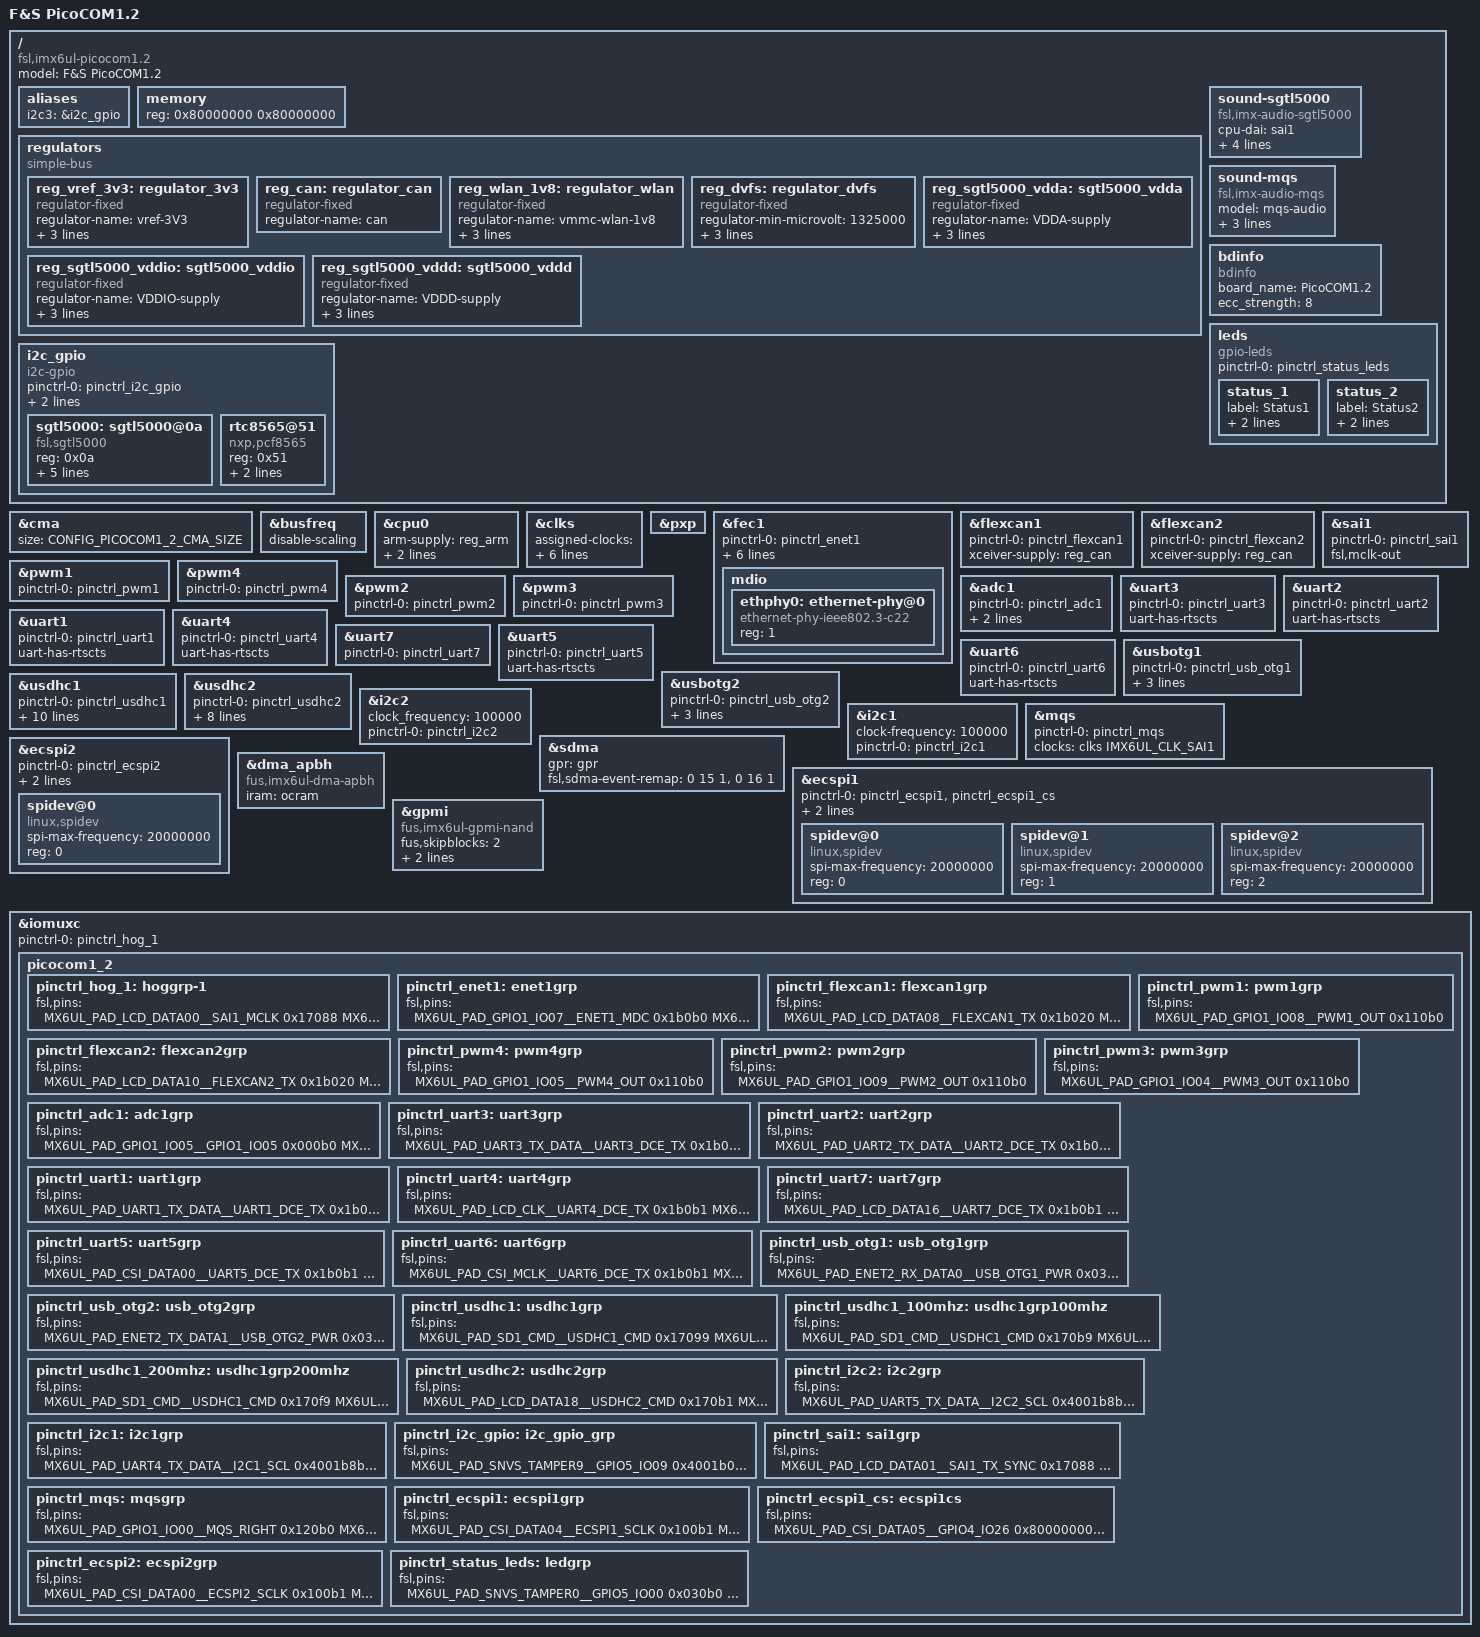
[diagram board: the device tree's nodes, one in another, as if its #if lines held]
/*
 * Copyright (C) 2016-2019 F&S Elektronik Systeme GmbH
 *
 * This program is free software; you can redistribute it and/or modify
 * it under the terms of the GNU General Public License version 2 as
 * published by the Free Software Foundation.
 */

/dts-v1/;

/* Set board revision as 3-digit number, e.g. 110 for board rev. 1.10 */
#define CONFIG_PICOCOM1_2_BOARD_REVISION	100

/* CMA: Set 64 MB for Continuous Memory Allocator */
#define CONFIG_PICOCOM1_2_CMA_SIZE 0x4000000

/* Ethernet, pins 1-4/71 */
#define CONFIG_PICOCOM1_2_ETH_A

/* WLAN/BLUETOOTH */
#define CONFIG_PICOCOM1_2_WLAN
//#define CONFIG_PICOCOM1_2_BLUETOOTH

/*
 * USB Device/OTG, pins 21/22/23. Set CONFIG_PICOCOM1_2_USB_OTG_HOST, if you
 * want to use OTG as a second host port, PWR is on pin 29 then.
 * ### TODO: Add support for role switch, ID is available on pin 17 as option.
 */
#define CONFIG_PICOCOM1_2_USB_OTG
//#define CONFIG_PICOCOM1_2_USB_OTG_HOST

/* USB Host, pins 19/20, PWR on pin 24 */
#define CONFIG_PICOCOM1_2_USB_HOST

/* CAN: CAN_A on pins 51/52, CAN_B on pins 53/54 */
#define CONFIG_PICOCOM1_2_CAN_A
#define CONFIG_PICOCOM1_2_CAN_B

/* I2C: I2C_A on pins 32/33, I2C_B on pins 12/11 */
#define CONFIG_PICOCOM1_2_I2C_A
#define CONFIG_PICOCOM1_2_I2C_B

/* PWM: PWM_A on pin 74, PWM_B on pin 75, PWM_C on pin 76, PWM_D on pin 70 */
#define CONFIG_PICOCOM1_2_PWM_A
#define CONFIG_PICOCOM1_2_PWM_B
#define CONFIG_PICOCOM1_2_PWM_C
#define CONFIG_PICOCOM1_2_PWM_D

/*
 * UART:
 * - UART_A with TXD/RXD/RTS/CTS on pins 17/18/49/50
 * - UART_B with TXD/RXD/RTS/CTS on pins 13-16
 * - UART_C with TXD/RXD/RTS/CTS on pins 43/44/41/40,
 * - UART_D with TXD/RXD/RTS/CTS on pins 45-48
 * - UART_E with TXD/RXD only on pins 67/68,
 * - UART_F with TXD/RXD/RTS/CTS on pins 63-66 (available if SPI_B is not used)
 * Comment the line with the RTSCTS macro if you just need TXD/RXD on a port
 */
#define CONFIG_PICOCOM1_2_UART_A
#define CONFIG_PICOCOM1_2_UART_A_RTSCTS
#define CONFIG_PICOCOM1_2_UART_B
#define CONFIG_PICOCOM1_2_UART_B_RTSCTS
#define CONFIG_PICOCOM1_2_UART_C
#define CONFIG_PICOCOM1_2_UART_C_RTSCTS
#define CONFIG_PICOCOM1_2_UART_D
#define CONFIG_PICOCOM1_2_UART_D_RTSCTS
#define CONFIG_PICOCOM1_2_UART_E
#define CONFIG_PICOCOM1_2_UART_F
#define CONFIG_PICOCOM1_2_UART_F_RTSCTS

/* SPI: SPI_A (3x CS) on pins 55-60, SPI_B (1x CS) on pins 63-66 */
#define CONFIG_PICOCOM1_2_SPI_A
#define CONFIG_PICOCOM1_2_SPI_B

/* Audio: Codec (SGTL5000) on pins 77-80 */
#define CONFIG_PICOCOM1_2_AUDIO

/*
 * MQS (Medium Quality Sound, playback only) on pins 77/78 is a hardware option
 * and only available if the SGTL5000 audio codec is not equipped.
 */
//#define CONFIG_PICOCOM1_2_MQS

/*
 * SD-Card, pins 34-39, CD on pin 40, WP on pin 41
 * The PicoCOM1 SKIT does not support CD and WP.
 */
#define CONFIG_PICOCOM1_2_SD_A
//#define CONFIG_PICOCOM1_2_SD_A_CD
//#define CONFIG_PICOCOM1_2_SD_A_WP

/*
 * ADC, pins 74-76. These pins are shared with PWM_A to PWM_C, so undefine the
 * PWM configs if you want to use them for analog input, otherwise you will
 * only measure the PWM level and the PWM output will work against the input.
 */
#define CONFIG_PICOCOM1_2_ADC


/* Check for invalid CONFIG combinations */

/* If SPI_B is active, UART_F can not be used */
#ifdef CONFIG_PICOCOM1_2_SPI_B
#undef CONFIG_PICOCOM1_2_UART_F
#undef CONFIG_PICOCOM1_2_UART_F_RTSCTS
#endif

/* If UART_C uses RTS/CTS, CD and WP for SD_A can not be used */
#ifdef CONFIG_PICOCOM1_2_UART_C_RTSCTS
#undef CONFIG_PICOCOM1_2_SD_A_CD
#undef CONFIG_PICOCOM1_2_SD_A_WP
#endif

/* If SGTL5000 audio is available, MQS audio can not be used */
#ifdef CONFIG_PICOCOM1_2_AUDIO
#undef CONFIG_PICOCOM1_2_MQS
#endif

/* If ADC is available, PWM_A - PWM_C can not be used */
#ifdef CONFIG_PICOCOM1_2_ADC
#undef CONFIG_PICOCOM1_2_PWM_A
#undef CONFIG_PICOCOM1_2_PWM_B
#undef CONFIG_PICOCOM1_2_PWM_C
#endif

#include <dt-bindings/input/input.h>
#include "imx6ul.dtsi"

/ {
	model = "F&S PicoCOM1.2";
	compatible = "fsl,imx6ul-picocom1.2", "fsl,imx6ul";

	aliases {
		i2c3 = &i2c_gpio;
	};

#if 0
chosen {
		stdout-path = &uart1;
	};
#endif
	memory {
		reg = <0x80000000 0x80000000>;
	};

	regulators {
		compatible = "simple-bus";
		#address-cells = <1>;
		#size-cells = <0>;

		reg_vref_3v3: regulator_3v3 {
			compatible = "regulator-fixed";
			regulator-name = "vref-3V3";
			regulator-min-microvolt = <3300000>;
			regulator-max-microvolt = <3300000>;
			regulator-always-on;
		};

		reg_can: regulator_can {
			compatible = "regulator-fixed";
			regulator-name = "can";
		};

#ifdef CONFIG_PICOCOM1_2_WLAN
		reg_wlan_1v8: regulator_wlan {
			compatible = "regulator-fixed";
			regulator-name = "vmmc-wlan-1v8";
			regulator-min-microvolt = <1800000>;
			regulator-max-microvolt = <1800000>;
			regulator-always-on;
		};
#endif

		reg_dvfs: regulator_dvfs {
			compatible = "regulator-fixed";
			regulator-min-microvolt = <1325000>;
			regulator-max-microvolt = <1325000>;
			regulator-name = "dvfs";
			regulator-always-on;
		};

		/* USB_OTG1_PWR done by USB controller, no regulator needed */
#if 0 //###
		reg_usb_otg1_vbus: usb_otg1_vbus {
			compatible = "regulator-fixed";
			regulator-name = "usb_otg1_vbus";
			regulator-min-microvolt = <5000000>;
			regulator-max-microvolt = <5000000>;
			gpio = <&gpio2 8 0>;
			enable-active-high;
		};
#endif //###

		/* USB_OTG2_PWR done by USB controller, no regulator needed */
#if 0 //###
		reg_usb_otg2_vbus: usb_otg2_vbus {
			compatible = "regulator-fixed";
			regulator-name = "usb_otg2_vbus";
			regulator-min-microvolt = <5000000>;
			regulator-max-microvolt = <5000000>;
			gpio = <&gpio2 12 0>;
			enable-active-high;
		};
#endif //###

#ifdef CONFIG_PICOCOM1_2_AUDIO
		/* SGTL5000 analog voltage */
		reg_sgtl5000_vdda: sgtl5000_vdda {
			compatible = "regulator-fixed";
			regulator-name = "VDDA-supply";
			regulator-min-microvolt = <3000000>;
			regulator-max-microvolt = <3000000>;
			regulator-always-on;
		};

		/* SGTL5000 I/O voltage */
		reg_sgtl5000_vddio: sgtl5000_vddio {
			compatible = "regulator-fixed";
			regulator-name = "VDDIO-supply";
			regulator-min-microvolt = <3300000>;
			regulator-max-microvolt = <3300000>;
			regulator-always-on;
		};

		/* SGTL5000 internal digital voltage */
		reg_sgtl5000_vddd: sgtl5000_vddd {
			compatible = "regulator-fixed";
			regulator-name = "VDDD-supply";
			regulator-min-microvolt = <1350000>;
			regulator-max-microvolt = <1350000>;
			regulator-always-on;
		};
#endif
	};

#ifdef CONFIG_PICOCOM1_2_AUDIO
	sound-sgtl5000 {
		compatible = "fsl,imx-audio-sgtl5000";
		cpu-dai = <&sai1>;
		audio-codec = <&sgtl5000>;
		model = "imx-sgtl5000";

		audio-routing =
		"LINE_IN", "Line In Jack",
		//"MIC_IN", "Mic Jack",
		//"Line Out Jack", "LINE_OUT",
		"Headphone Jack", "HP_OUT";
	};
#endif

#ifdef CONFIG_PICOCOM1_2_MQS
	sound-mqs {
		compatible = "fsl,imx-audio-mqs";
		model = "mqs-audio";
		cpu-dai = <&sai1>;
		asrc-controller = <&asrc>;
		audio-codec = <&mqs>;
	};
#endif

	/* Internal I2C (bitbanging) */
	i2c_gpio: i2c_gpio {
		pinctrl-names = "default";
		pinctrl-0 = <&pinctrl_i2c_gpio>;
		compatible = "i2c-gpio";
		gpios = <&gpio5 8 0 /* sda */
			 &gpio5 9 0 /* scl */
			>;
//###		i2c-gpio,sda-open-drain;
//###		i2c-gpio,scl-open-drain;
		i2c-gpio,delay-us = <2>;	/* ~100 kHz */
		#address-cells = <1>;
		#size-cells = <0>;
	};

	/* F&S board information */
	bdinfo {
		compatible = "bdinfo";
		board_name = "PicoCOM1.2";
		ecc_strength = "8";
	};

	leds {
		compatible = "gpio-leds";
		pinctrl-names = "default";
		pinctrl-0 = <&pinctrl_status_leds>;

		status_1 {
			label = "Status1";
			gpios = <&gpio5 0 GPIO_ACTIVE_HIGH>;
			default-state = "keep";
		};

		status_2 {
			label = "Status2";
			gpios = <&gpio5 1 GPIO_ACTIVE_HIGH>;
			default-state = "keep";
		};
	};
};

/* RAM size for Continues Memory Allocator */
&cma {
	size = <CONFIG_PICOCOM1_2_CMA_SIZE>;
};

&busfreq {
	/* Disable bus frequency scaling, because reducing bus frequency to
	   24 MHz does not work with all types of DDR3 RAM */
	disable-scaling;
};

&cpu0 {
	arm-supply = <&reg_arm>;
	soc-supply = <&reg_soc>;
	dc-supply = <&reg_dvfs>;
};

&clks {
	/* Set audio clock rate, output on CKO1 */
	assigned-clocks = <&clks IMX6UL_CLK_PLL4_AUDIO_DIV>,
			<&clks IMX6UL_CLK_SAI1_SEL>,
			<&clks IMX6UL_CLK_SAI1>;

	assigned-clock-parents =<0>,
			<&clks IMX6UL_CLK_PLL4_AUDIO_DIV>,
			<0>;

#ifdef CONFIG_PICOCOM1_2_MQS
	assigned-clock-rates = <786432000>, <0>, <24576000>;
#elif defined(CONFIG_PICOCOM1_2_AUDIO)
	assigned-clock-rates = <786432000>, <0>, <12288000>;
#endif
};

&pxp {
	status = "okay";
};

#ifdef CONFIG_PICOCOM1_2_ETH_A
&fec1 {
	pinctrl-names = "default";
	pinctrl-0 = <&pinctrl_enet1>;
	assigned-clocks = <&clks IMX6UL_CLK_ENET_REF>;
	assigned-clock-rates = <50000000>;
	phy-mode = "rmii";
	phy-handle = <&ethphy0>;
	phy-supply = <&reg_vref_3v3>;
	fsl,ref-clock-out;
	status = "okay";

	mdio {
		#address-cells = <1>;
		#size-cells = <0>;

		ethphy0: ethernet-phy@0 {
			compatible = "ethernet-phy-ieee802.3-c22";
			reg = <1>;
		};
	};
};
#endif

#ifdef CONFIG_PICOCOM1_2_CAN_A
&flexcan1 {
	pinctrl-names = "default";
	pinctrl-0 = <&pinctrl_flexcan1>;
	xceiver-supply = <&reg_can>;
	status = "okay";
};
#endif

#ifdef CONFIG_PICOCOM1_2_CAN_B
&flexcan2 {
	pinctrl-names = "default";
	pinctrl-0 = <&pinctrl_flexcan2>;
	xceiver-supply = <&reg_can>;
	status = "okay";
};
#endif

#ifdef CONFIG_PICOCOM1_2_PWM_A
/* PWM_A implemented by PWM1 */
&pwm1 {
	pinctrl-names = "default";
	pinctrl-0 = <&pinctrl_pwm1>;
	status = "okay";
};
#endif

#ifdef CONFIG_PICOCOM1_2_PWM_B
/* PWM_B implemented by PWM4 */
&pwm4 {
	pinctrl-names = "default";
	pinctrl-0 = <&pinctrl_pwm4>;
	status = "okay";
};
#endif

#ifdef CONFIG_PICOCOM1_2_PWM_C
/* PWM_C implemented by PWM2 */
&pwm2 {
	pinctrl-names = "default";
	pinctrl-0 = <&pinctrl_pwm2>;
	status = "okay";
};
#endif

#ifdef CONFIG_PICOCOM1_2_PWM_D
/* PWM_D implemented by PWM3 */
&pwm3 {
	pinctrl-names = "default";
	pinctrl-0 = <&pinctrl_pwm3>;
	status = "okay";
};
#endif

#ifdef CONFIG_PICOCOM1_2_ADC
&adc1 {
	pinctrl-names = "default";
	pinctrl-0 = <&pinctrl_adc1>;
	vref-supply = <&reg_vref_3v3>;
	num-channels = <10>;
	status = "okay";
};
#endif

#if defined(CONFIG_PICOCOM1_2_AUDIO) || defined(CONFIG_PICOCOM1_2_MQS)
/* SAI1 is needed by SGTL5000 codec and by MQS audio */
&sai1 {
	pinctrl-names = "default";
	pinctrl-0 = <&pinctrl_sai1>;
	fsl,mclk-out;
	status = "okay";
};
#endif

#ifdef CONFIG_PICOCOM1_2_UART_A
/* UART_A implemented by UART3 */
&uart3 {
	pinctrl-names = "default";
	pinctrl-0 = <&pinctrl_uart3>;
#ifdef CONFIG_PICOCOM1_2_UART_A_RTSCTS
	uart-has-rtscts;
#endif
	status = "okay";
};
#endif

#ifdef CONFIG_PICOCOM1_2_UART_B
/* UART_B implemented by UART2 */
&uart2 {
	pinctrl-names = "default";
	pinctrl-0 = <&pinctrl_uart2>;
#ifdef CONFIG_PICOCOM1_2_UART_B_RTSCTS
	uart-has-rtscts;
#endif
	status = "okay";
};
#endif

#ifdef CONFIG_PICOCOM1_2_UART_C
/* UART_C implemented by UART1 */
&uart1 {
	pinctrl-names = "default";
	pinctrl-0 = <&pinctrl_uart1>;
#ifdef CONFIG_PICOCOM1_2_UART_C_RTSCTS
	uart-has-rtscts;
#endif
	status = "okay";
};
#endif

#ifdef CONFIG_PICOCOM1_2_UART_D
/* UART_D implemented by UART4 */
&uart4 {
	pinctrl-names = "default";
	pinctrl-0 = <&pinctrl_uart4>;
#ifdef CONFIG_PICOCOM1_2_UART_D_RTSCTS
	uart-has-rtscts;
#endif
	status = "okay";
};
#endif

#ifdef CONFIG_PICOCOM1_2_UART_E
/* UART_E implemented by UART7, no RTS/CTS */
&uart7 {
	pinctrl-names = "default";
	pinctrl-0 = <&pinctrl_uart7>;
	status = "okay";
};
#endif

#ifdef CONFIG_PICOCOM1_2_UART_F
/* UART_F implemented by UART5 */
&uart5 {
	pinctrl-names = "default";
	pinctrl-0 = <&pinctrl_uart5>;
#ifdef CONFIG_PICOCOM1_2_UART_F_RTSCTS
	uart-has-rtscts;
#endif
	status = "okay";
};
#endif

#ifdef CONFIG_PICOCOM1_2_BLUETOOTH
/* UART6 is used to communicate with bluetooth */
&uart6 {
	pinctrl-names = "default";
	pinctrl-0 = <&pinctrl_uart6>;
	uart-has-rtscts;
	status = "okay";
};
#endif

#ifdef CONFIG_PICOCOM1_2_USB_OTG
/* USB Device/OTG, may be used as second host */
&usbotg1 {
	pinctrl-names = "default";
	pinctrl-0 = <&pinctrl_usb_otg1>;
#ifdef CONFIG_PICOCOM1_2_USB_OTG_HOST
	dr_mode = "host";
//###	vbus-supply = <&reg_usb_otg1_vbus>;
	pwr-active-high;
	disable-over-current;
#else
	dr_mode = "peripheral";
#endif
	status = "okay";
};
#endif

#ifdef CONFIG_PICOCOM1_2_USB_HOST
/* USB host is implemented by OTG2 */
&usbotg2 {
	pinctrl-names = "default";
	pinctrl-0 = <&pinctrl_usb_otg2>;
//###	vbus-supply = <&reg_usb_otg2_vbus>;
	dr_mode = "host";
	pwr-active-high;
	disable-over-current;
	status = "okay";
};
#endif

#ifdef CONFIG_PICOCOM1_2_WLAN
/* On-board WLAN uses USDHC1 */
&usdhc1 {
	pinctrl-names = "default", "state_100mhz", "state_200mhz";
	pinctrl-0 = <&pinctrl_usdhc1>;
	pinctrl-1 = <&pinctrl_usdhc1_100mhz>;
	pinctrl-2 = <&pinctrl_usdhc1_200mhz>;
	non-removable;
	bus-width = <4>;
	vmmc-supply = <&reg_wlan_1v8>;	/* VDD */
	vqmmc-supply = <&reg_vref_3v3>;	/* VDD_IO */
	voltage-ranges = <3300 3300>;
	no-1-8-v;
	keep-power-in-suspend;
	enable-sdio-wakeup;
	status = "okay";
};
#endif

#ifdef CONFIG_PICOCOM1_2_SD_A
/* SD_A implemented by USDHC2 */
&usdhc2 {
	pinctrl-names = "default";
	pinctrl-0 = <&pinctrl_usdhc2>;
#ifdef CONFIG_PICOCOM1_2_SD_A_CD
	cd-gpios = <&gpio1 19 GPIO_ACTIVE_LOW>;
#else
	non-removable;
#endif
#ifdef CONFIG_PICOCOM1_2_SD_A_WP
	wp-gpios = <&gpio1 18 GPIO_ACTIVE_HIGH>;
#endif
	bus-width = <4>;
	vmmc-supply = <&reg_vref_3v3>;	/* VDD */
	vqmmc-supply = <&reg_vref_3v3>;	/* VDD_IO */
	voltage-ranges = <3300 3300>;
	no-1-8-v;
	keep-power-in-suspend;
	status = "okay";
};
#endif

#ifdef CONFIG_PICOCOM1_2_I2C_A
/* I2C_A implemented by I2C2 */
&i2c2 {
	clock_frequency = <100000>;
	pinctrl-names = "default";
	pinctrl-0 = <&pinctrl_i2c2>;
	status = "okay";
};
#endif

#ifdef CONFIG_PICOCOM1_2_I2C_B
/* I2C_B implemented by I2C1 */
&i2c1 {
	clock-frequency = <100000>;
	pinctrl-names = "default";
	pinctrl-0 = <&pinctrl_i2c1>;
	status = "okay";
};
#endif

/* Internal I2C (bitbanging): RTC (PCA8565), SGTL5000 (SKIT) */
&i2c_gpio {
#ifdef CONFIG_PICOCOM1_2_AUDIO
	sgtl5000: sgtl5000@0a {
		compatible = "fsl,sgtl5000";
		reg = <0x0a>;
		clocks = <&clks IMX6UL_CLK_SAI1>;
		mono2both;
		VDDA-supply = <&reg_sgtl5000_vdda>;
		VDDIO-supply = <&reg_sgtl5000_vddio>;
		VDDD-supply = <&reg_sgtl5000_vddd>;
	};
#endif

	rtc8565@51 {
		compatible = "nxp,pcf8565", "nxp,pcf8563";
		reg = <0x51>;
		interrupt-parent = <&gpio5>;
		interrupts = <7 IRQ_TYPE_EDGE_FALLING>;
	};
};

#ifdef CONFIG_PICOCOM1_2_MQS
&mqs {
	pinctrl-names = "default";
	pinctrl-0 = <&pinctrl_mqs>;
	clocks = <&clks IMX6UL_CLK_SAI1>;
	clock-names = "mclk";
	status = "okay";
};

&sdma {
	gpr = <&gpr>;
	fsl,sdma-event-remap = <0 15 1>, <0 16 1>;
};
#endif

#ifdef CONFIG_PICOCOM1_2_SPI_A
/* SPI_A (3x CS) imlpemented by ECSPI1 */
&ecspi1 {
	pinctrl-names = "default";
	pinctrl-0 = <&pinctrl_ecspi1 &pinctrl_ecspi1_cs>;
	cs-gpios = <&gpio4 26 0>, <&gpio3 10 0>, <&gpio3 11 0>;
	fsl,spi-num-chipselects = <3>;
	status = "okay";

	spidev@0 {
		#address-cells = <1>;
		#size-cells = <1>;
		compatible = "linux,spidev";
		spi-max-frequency = <20000000>;
		reg = <0>;
	};

	spidev@1 {
		#address-cells = <1>;
		#size-cells = <1>;
		compatible = "linux,spidev";
		spi-max-frequency = <20000000>;
		reg = <1>;
	};

	spidev@2 {
		#address-cells = <1>;
		#size-cells = <1>;
		compatible = "linux,spidev";
		spi-max-frequency = <20000000>;
		reg = <2>;
	};
};
#endif

#ifdef CONFIG_PICOCOM1_2_SPI_B
/* SPI_B (1x CS) */
&ecspi2 {
	pinctrl-names = "default";
	pinctrl-0 = <&pinctrl_ecspi2>;
	cs-gpios = <&gpio4 22 0>;
	fsl,spi-num-chipselects = <1>;
	status = "okay";

	spidev@0 {
		#address-cells = <1>;
		#size-cells = <1>;
		compatible = "linux,spidev";
		spi-max-frequency = <20000000>;
		reg = <0>;
	};
};
#endif

&dma_apbh {
	/* Switch to F&S implementation of APBH DMA driver for GPMI (NAND) */
	compatible = "fus,imx6ul-dma-apbh", "fus,imx28-dma-apbh";
	iram = <&ocram>;
};

&gpmi {
	/* Switch to F&S implementation of GPMI NAND driver */
	compatible = "fus,imx6ul-gpmi-nand", "fus,imx6q-gpmi-nand";
	pinctrl-names = "default";
//###	pinctrl-0 = <&pinctrl_gpmi_nand_1>;
	fus,skipblocks = <2>;
	fus,chunk1k;
	fus,ecc_strength = <8>;
	status = "okay";
};

&iomuxc {
	pinctrl-names = "default";
	pinctrl-0 = <&pinctrl_hog_1>;
	picocom1_2 {

		pinctrl_hog_1: hoggrp-1 {
				fsl,pins = <
				MX6UL_PAD_LCD_DATA00__SAI1_MCLK		0x17088
				//MX6UL_PAD_SNVS_TAMPER7__GPIO5_IO07	0x0b0b0
				/* GPIO1 - GPIO5 */
				MX6UL_PAD_LCD_DATA12__GPIO3_IO17	0x030b0
				MX6UL_PAD_LCD_DATA13__GPIO3_IO18	0x030b0
				MX6UL_PAD_LCD_DATA14__GPIO3_IO19	0x030b0
				MX6UL_PAD_LCD_DATA15__GPIO3_IO20	0x030b0
				MX6UL_PAD_LCD_DATA07__GPIO3_IO12	0x030b0
			>;

};

#ifdef CONFIG_PICOCOM1_2_ETH_A
		pinctrl_enet1: enet1grp {
			fsl,pins = <
				/* MDIO */
				MX6UL_PAD_GPIO1_IO07__ENET1_MDC		0x1b0b0
				MX6UL_PAD_GPIO1_IO06__ENET1_MDIO	0x1b829

				/* FEC1 */
				MX6UL_PAD_ENET1_RX_EN__ENET1_RX_EN	0x1b0b0
				MX6UL_PAD_ENET1_RX_ER__ENET1_RX_ER	0x1b0b0
				MX6UL_PAD_ENET1_RX_DATA1__ENET1_RDATA01	0x1b0b0
				MX6UL_PAD_ENET1_RX_DATA0__ENET1_RDATA00	0x1b0b0
				MX6UL_PAD_ENET1_TX_EN__ENET1_TX_EN	0x1b0b0
				MX6UL_PAD_ENET1_TX_DATA1__ENET1_TDATA01	0x1b0b0
				MX6UL_PAD_ENET1_TX_DATA0__ENET1_TDATA00	0x1b0b0
				MX6UL_PAD_ENET1_TX_CLK__ENET1_REF_CLK1	0x4001b0b0

				/* phy reset */
				MX6UL_PAD_BOOT_MODE1__GPIO5_IO11	0x0b0b0
			>;
		};
#endif

#ifdef CONFIG_PICOCOM1_2_CAN_A
		pinctrl_flexcan1: flexcan1grp{
			fsl,pins = <
				MX6UL_PAD_LCD_DATA08__FLEXCAN1_TX	0x1b020
				MX6UL_PAD_LCD_DATA09__FLEXCAN1_RX	0x1b020
			>;
		};
#endif

#ifdef CONFIG_PICOCOM1_2_CAN_B
		pinctrl_flexcan2: flexcan2grp{
			fsl,pins = <
				MX6UL_PAD_LCD_DATA10__FLEXCAN2_TX	0x1b020
				MX6UL_PAD_LCD_DATA11__FLEXCAN2_RX	0x1b020
			>;
		};
#endif

#ifdef CONFIG_PICOCOM1_2_PWM_A
		pinctrl_pwm1: pwm1grp {
			fsl,pins = <
				MX6UL_PAD_GPIO1_IO08__PWM1_OUT		0x110b0
			>;
		};
#endif

#ifdef CONFIG_PICOCOM1_2_PWM_B
		pinctrl_pwm4: pwm4grp {
			fsl,pins = <
				MX6UL_PAD_GPIO1_IO05__PWM4_OUT		0x110b0
			>;
		};
#endif

#ifdef CONFIG_PICOCOM1_2_PWM_C
		pinctrl_pwm2: pwm2grp {
			fsl,pins = <
				MX6UL_PAD_GPIO1_IO09__PWM2_OUT		0x110b0
			>;
		};
#endif

#ifdef CONFIG_PICOCOM1_2_PWM_D
		pinctrl_pwm3: pwm3grp {
			fsl,pins = <
				MX6UL_PAD_GPIO1_IO04__PWM3_OUT		0x110b0
			>;
		};
#endif

#ifdef CONFIG_PICOCOM1_2_ADC
		pinctrl_adc1: adc1grp {
			fsl,pins = <
				MX6UL_PAD_GPIO1_IO05__GPIO1_IO05	0x000b0
				MX6UL_PAD_GPIO1_IO08__GPIO1_IO08	0x000b0
				MX6UL_PAD_GPIO1_IO09__GPIO1_IO09	0x000b0
			>;
		};
#endif

#ifdef CONFIG_PICOCOM1_2_UART_A
		pinctrl_uart3: uart3grp {
			fsl,pins = <
				MX6UL_PAD_UART3_TX_DATA__UART3_DCE_TX	0x1b0b1
				MX6UL_PAD_UART3_RX_DATA__UART3_DCE_RX	0x1b0b1
#ifdef CONFIG_PICOCOM1_2_UART_A_RTSCTS
				MX6UL_PAD_UART3_RTS_B__UART3_DCE_RTS	0x1b0b1
				MX6UL_PAD_UART3_CTS_B__UART3_DCE_CTS	0x1b0b1
#endif
			>;
		};
#endif

#ifdef CONFIG_PICOCOM1_2_UART_B
		pinctrl_uart2: uart2grp {
			fsl,pins = <
				MX6UL_PAD_UART2_TX_DATA__UART2_DCE_TX	0x1b0b1
				MX6UL_PAD_UART2_RX_DATA__UART2_DCE_RX	0x1b0b1
#ifdef CONFIG_PICOCOM1_2_UART_B_RTSCTS
				MX6UL_PAD_UART2_RTS_B__UART2_DCE_RTS	0x1b0b1
				MX6UL_PAD_UART2_CTS_B__UART2_DCE_CTS	0x1b0b1
#endif
			>;
		};
#endif

#ifdef CONFIG_PICOCOM1_2_UART_C
		pinctrl_uart1: uart1grp {
			fsl,pins = <
				MX6UL_PAD_UART1_TX_DATA__UART1_DCE_TX	0x1b0b1
				MX6UL_PAD_UART1_RX_DATA__UART1_DCE_RX	0x1b0b1

#ifdef CONFIG_PICOCOM1_2_UART_C_RTSCTS
				MX6UL_PAD_UART1_RTS_B__UART1_DCE_RTS	0x1b0b1
				MX6UL_PAD_UART1_CTS_B__UART1_DCE_CTS	0x1b0b1
#endif
			>;
		};
#endif

#ifdef CONFIG_PICOCOM1_2_UART_D
		pinctrl_uart4: uart4grp {
			fsl,pins = <
				MX6UL_PAD_LCD_CLK__UART4_DCE_TX		0x1b0b1
				MX6UL_PAD_LCD_ENABLE__UART4_DCE_RX	0x1b0b1
#ifdef CONFIG_PICOCOM1_2_UART_D_RTSCTS
				MX6UL_PAD_LCD_HSYNC__UART4_DCE_CTS	0x1b0b1
				MX6UL_PAD_LCD_VSYNC__UART4_DCE_RTS	0x1b0b1
#endif
			>;
		};
#endif

#ifdef CONFIG_PICOCOM1_2_UART_E
		pinctrl_uart7: uart7grp {
			fsl,pins = <
				MX6UL_PAD_LCD_DATA16__UART7_DCE_TX	0x1b0b1
				MX6UL_PAD_LCD_DATA17__UART7_DCE_RX	0x1b0b1
			>;
		};
#endif

#ifdef CONFIG_PICOCOM1_2_UART_F
		pinctrl_uart5: uart5grp {
			fsl,pins = <
				MX6UL_PAD_CSI_DATA00__UART5_DCE_TX	0x1b0b1
				MX6UL_PAD_CSI_DATA01__UART5_DCE_RX	0x1b0b1
#ifdef CONFIG_PICOCOM1_2_UART_F_RTSCTS
				MX6UL_PAD_CSI_DATA02__UART5_DTE_CTS	0x1b0b1
				MX6UL_PAD_CSI_DATA03__UART5_DTE_RTS	0x1b0b1
#endif
			>;
		};
#endif

#ifdef CONFIG_PICOCOM1_2_BLUETOOTH
		pinctrl_uart6: uart6grp {
			fsl,pins = <
				MX6UL_PAD_CSI_MCLK__UART6_DCE_TX	0x1b0b1
				MX6UL_PAD_CSI_PIXCLK__UART6_DCE_RX	0x1b0b1
				MX6UL_PAD_CSI_VSYNC__UART6_DTE_CTS	0x1b0b1
				MX6UL_PAD_CSI_HSYNC__UART6_DTE_RTS	0x1b0b1
			>;
		};
#endif

#ifdef CONFIG_PICOCOM1_2_USB_OTG
		pinctrl_usb_otg1: usb_otg1grp {
			fsl,pins = <
#ifdef CONFIG_PICOCOM1_2_USB_OTG_HOST
				/* USB_OTG1_PWR, active high */
//###				MX6UL_PAD_ENET2_RX_DATA0__GPIO2_IO08	0x030b0
				MX6UL_PAD_ENET2_RX_DATA0__USB_OTG1_PWR	0x030b0
#endif
			>;
		};
#endif

#ifdef CONFIG_PICOCOM1_2_USB_HOST
		pinctrl_usb_otg2: usb_otg2grp {
			fsl,pins = <
				/* USB_OTG2_PWR, active high */
//###				MX6UL_PAD_ENET2_TX_DATA1__GPIO2_IO12	0x030b0
				MX6UL_PAD_ENET2_TX_DATA1__USB_OTG2_PWR	0x030b0
			>;
		};
#endif

#ifdef CONFIG_PICOCOM1_2_WLAN
		pinctrl_usdhc1: usdhc1grp {
			fsl,pins = <
				MX6UL_PAD_SD1_CMD__USDHC1_CMD		0x17099
				MX6UL_PAD_SD1_CLK__USDHC1_CLK		0x10091
				MX6UL_PAD_SD1_DATA0__USDHC1_DATA0	0x17099
				MX6UL_PAD_SD1_DATA1__USDHC1_DATA1	0x17099
				MX6UL_PAD_SD1_DATA2__USDHC1_DATA2	0x17099
				MX6UL_PAD_SD1_DATA3__USDHC1_DATA3	0x17099
			>;
		};

		pinctrl_usdhc1_100mhz: usdhc1grp100mhz {
			fsl,pins = <
				MX6UL_PAD_SD1_CMD__USDHC1_CMD		0x170b9
				MX6UL_PAD_SD1_CLK__USDHC1_CLK		0x100b9
				MX6UL_PAD_SD1_DATA0__USDHC1_DATA0	0x170b9
				MX6UL_PAD_SD1_DATA1__USDHC1_DATA1	0x170b9
				MX6UL_PAD_SD1_DATA2__USDHC1_DATA2	0x170b9
				MX6UL_PAD_SD1_DATA3__USDHC1_DATA3	0x170b9
			>;
		};

		pinctrl_usdhc1_200mhz: usdhc1grp200mhz {
			fsl,pins = <
				MX6UL_PAD_SD1_CMD__USDHC1_CMD		0x170f9
				MX6UL_PAD_SD1_CLK__USDHC1_CLK		0x100f9
				MX6UL_PAD_SD1_DATA0__USDHC1_DATA0	0x170f9
				MX6UL_PAD_SD1_DATA1__USDHC1_DATA1	0x170f9
				MX6UL_PAD_SD1_DATA2__USDHC1_DATA2	0x170f9
				MX6UL_PAD_SD1_DATA3__USDHC1_DATA3	0x170f9
			>;
		};
#endif

#ifdef CONFIG_PICOCOM1_2_SD_A
		pinctrl_usdhc2: usdhc2grp {
			fsl,pins = <
				MX6UL_PAD_LCD_DATA18__USDHC2_CMD	0x170b1
				MX6UL_PAD_LCD_DATA19__USDHC2_CLK	0x100b1
				MX6UL_PAD_LCD_DATA20__USDHC2_DATA0	0x170b1
				MX6UL_PAD_LCD_DATA21__USDHC2_DATA1	0x170b1
				MX6UL_PAD_LCD_DATA22__USDHC2_DATA2	0x170b1
				MX6UL_PAD_LCD_DATA23__USDHC2_DATA3	0x170b1
#ifdef CONFIG_PICOCOM1_2_SD_A_CD
				/* Card Detect (CD), active low (pull-up) */
				MX6UL_PAD_UART1_RTS_B__GPIO1_IO19	0x17000
#endif
#ifdef CONFIG_PICOCOM1_2_SD_A_WP
				/*
				 * Write Protect (WP), active high (pull-up)
				 * lock:   WP switch open, pulled high
				 * unlock: WP switch closed, connects to GND
				 */
				MX6UL_PAD_UART1_CTS_B__GPIO1_IO18	0x17000
#endif
			>;
		};
#endif

#ifdef CONFIG_PICOCOM1_2_I2C_A
		pinctrl_i2c2: i2c2grp {
			fsl,pins = <
				MX6UL_PAD_UART5_TX_DATA__I2C2_SCL	0x4001b8b0
				MX6UL_PAD_UART5_RX_DATA__I2C2_SDA	0x4001b8b0
			>;
		};
#endif

#ifdef CONFIG_PICOCOM1_2_I2C_B
		pinctrl_i2c1: i2c1grp {
			fsl,pins = <
				MX6UL_PAD_UART4_TX_DATA__I2C1_SCL	0x4001b8b0
				MX6UL_PAD_UART4_RX_DATA__I2C1_SDA	0x4001b8b0
			>;
		};
#endif

		pinctrl_i2c_gpio: i2c_gpio_grp {
			fsl,pins = <
				MX6UL_PAD_SNVS_TAMPER9__GPIO5_IO09	0x4001b0b0
				MX6UL_PAD_SNVS_TAMPER8__GPIO5_IO08	0x4001b0b0
				/* RTC IRQ (unused) */
				MX6UL_PAD_SNVS_TAMPER7__GPIO5_IO07	0x4001b0b0
			>;
		};

#if defined(CONFIG_PICOCOM1_2_AUDIO) || defined(CONFIG_PICOCOM1_2_MQS)
		pinctrl_sai1: sai1grp {
			fsl,pins = <
				MX6UL_PAD_LCD_DATA01__SAI1_TX_SYNC	0x17088
				MX6UL_PAD_LCD_DATA02__SAI1_TX_BCLK	0x17088
				MX6UL_PAD_LCD_DATA03__SAI1_RX_DATA	0x17088
				MX6UL_PAD_LCD_DATA04__SAI1_TX_DATA	0x17088
			>;
		};
#endif

#ifdef CONFIG_PICOCOM1_2_MQS
		pinctrl_mqs: mqsgrp {
			fsl,pins = <
				MX6UL_PAD_GPIO1_IO00__MQS_RIGHT		0x120b0
				MX6UL_PAD_GPIO1_IO01__MQS_LEFT		0x120b0
			>;
		};
#endif

#ifdef CONFIG_PICOCOM1_2_SPI_A
		pinctrl_ecspi1: ecspi1grp {
			fsl,pins = <
				MX6UL_PAD_CSI_DATA04__ECSPI1_SCLK	0x100b1
				MX6UL_PAD_CSI_DATA06__ECSPI1_MOSI	0x100b1
				MX6UL_PAD_CSI_DATA07__ECSPI1_MISO	0x100b1
			>;
		};

		pinctrl_ecspi1_cs: ecspi1cs {
			fsl,pins = <
				MX6UL_PAD_CSI_DATA05__GPIO4_IO26	0x80000000
				MX6UL_PAD_LCD_DATA05__GPIO3_IO10	0x80000000
				MX6UL_PAD_LCD_DATA06__GPIO3_IO11	0x80000000
			>;
		};
#endif

#ifdef CONFIG_PICOCOM1_2_SPI_B
		pinctrl_ecspi2: ecspi2grp {
			fsl,pins = <
				MX6UL_PAD_CSI_DATA00__ECSPI2_SCLK	0x100b1
				MX6UL_PAD_CSI_DATA01__GPIO4_IO22	0x80000000
				MX6UL_PAD_CSI_DATA02__ECSPI2_MOSI	0x100b1
				MX6UL_PAD_CSI_DATA03__ECSPI2_MISO	0x100b1
			>;
		};
#endif

#if 0
		pinctrl_gpmi_nand_1: gpmi-nand-1 {
			/* Already configured in NBoot/U-Boot */
			fsl,pins = <
				MX6UL_PAD_NAND_CLE__RAWNAND_CLE		0x0b0b1
				MX6UL_PAD_NAND_ALE__RAWNAND_ALE		0x0b0b1
				MX6UL_PAD_NAND_WP_B__RAWNAND_WP_B	0x0b0b1
				MX6UL_PAD_NAND_READY_B__RAWNAND_READY_B	0x0b000
				MX6UL_PAD_NAND_CE0_B__RAWNAND_CE0_B	0x0b0b1
				//MX6UL_PAD_NAND_CE1_B__RAWNAND_CE1_B	0x0b0b1
				MX6UL_PAD_NAND_RE_B__RAWNAND_RE_B	0x0b0b1
				MX6UL_PAD_NAND_WE_B__RAWNAND_WE_B	0x0b0b1
				MX6UL_PAD_NAND_DATA00__RAWNAND_DATA00	0x0b0b1
				MX6UL_PAD_NAND_DATA01__RAWNAND_DATA01	0x0b0b1
				MX6UL_PAD_NAND_DATA02__RAWNAND_DATA02	0x0b0b1
				MX6UL_PAD_NAND_DATA03__RAWNAND_DATA03	0x0b0b1
				MX6UL_PAD_NAND_DATA04__RAWNAND_DATA04	0x0b0b1
				MX6UL_PAD_NAND_DATA05__RAWNAND_DATA05	0x0b0b1
				MX6UL_PAD_NAND_DATA06__RAWNAND_DATA06	0x0b0b1
				MX6UL_PAD_NAND_DATA07__RAWNAND_DATA07	0x0b0b1
			>;
		};
#endif

		pinctrl_status_leds: ledgrp {
			fsl,pins = <
				MX6UL_PAD_SNVS_TAMPER0__GPIO5_IO00	0x030b0
				MX6UL_PAD_SNVS_TAMPER1__GPIO5_IO01	0x030b0
			>;
		};
	};
};
